AUTOSAR XML (schema 00046)
package /ComponentTypes
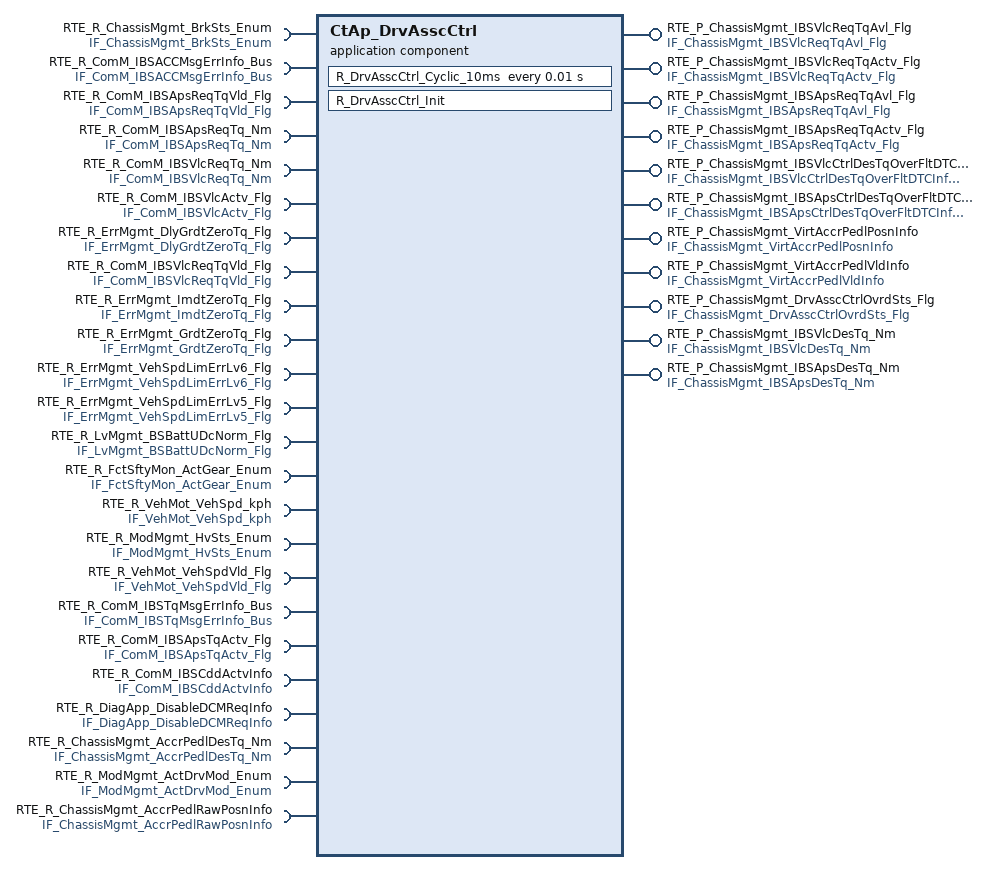
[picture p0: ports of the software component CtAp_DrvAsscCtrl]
  application sw component type CtAp_DrvAsscCtrl
    4 x provide port:
      RTE_P_ChassisMgmt_IBSVlcReqTqAvl_Flg: nonqueued-sender-com-spec{data-element=tec_ChassisMgmt_IBSVlcReqTqAvl_Flg, init-value=0}, provided-interface=IF_ChassisMgmt_IBSVlcReqTqAvl_Flg
      RTE_P_ChassisMgmt_IBSVlcReqTqActv_Flg: nonqueued-sender-com-spec{data-element=tec_ChassisMgmt_IBSVlcReqTqActv_Flg, init-value=0}, provided-interface=IF_ChassisMgmt_IBSVlcReqTqActv_Flg
      RTE_P_ChassisMgmt_IBSApsReqTqAvl_Flg: nonqueued-sender-com-spec{data-element=tec_ChassisMgmt_IBSApsReqTqAvl_Flg, init-value=0}, provided-interface=IF_ChassisMgmt_IBSApsReqTqAvl_Flg
      RTE_P_ChassisMgmt_IBSApsReqTqActv_Flg: nonqueued-sender-com-spec{data-element=tec_ChassisMgmt_IBSApsReqTqActv_Flg, init-value=0}, provided-interface=IF_ChassisMgmt_IBSApsReqTqActv_Flg
    16 x require port:
      RTE_R_ChassisMgmt_BrkSts_Enum: nonqueued-receiver-com-spec{data-element=tec_ChassisMgmt_BrkSts_Enum, filter=data-filter-type=ALWAYS, init-value=0}, required-interface=IF_ChassisMgmt_BrkSts_Enum
      RTE_R_ComM_IBSACCMsgErrInfo_Bus: required-interface=IF_ComM_IBSACCMsgErrInfo_Bus
        required-com-specs:
          data-element=tec_ComM_IBSACCCRCDTCInfo_Bus, filter=data-filter-type=ALWAYS, init-value=fields=[ComM_MonStatIBSACCCRCDTCErrorInfo:0, ComM_MonResIBSACCCRCDTCErrorInfo:0, ComM_ErrStatIBSACCCRCDTCErrorInfo:0, ComM_ErrResIBSACCCRCDTCErrorInfo:0]
          data-element=tec_ComM_IBSACCCRCInfo_Bus, filter=data-filter-type=ALWAYS, init-value=fields=[ComM_MonStatIBSACCCRCErrorInfo:0, ComM_MonResIBSACCCRCErrorInfo:0, ComM_ErrStatIBSACCCRCErrorInfo:0, ComM_ErrResIBSACCCRCErrorInfo:0]
          data-element=tec_ComM_IBSACCTimeoutDTCInfo_Bus, filter=data-filter-type=ALWAYS, init-value=fields=[ComM_MonStatIBSACCTimeoutDTCErrorInfo:0, ComM_MonResIBSACCTimeoutDTCErrorInfo:0, ComM_ErrStatIBSACCTimeoutDTCErrorInfo:0, ComM_ErrResIBSACCTimeoutDTCErrorInfo:0]
          data-element=tec_ComM_IBSACCE2ETimeoutInfo_Bus, filter=data-filter-type=ALWAYS, init-value=fields=[ComM_MonStatIBSACCE2ETimeoutInfo:0, ComM_MonResIBSACCE2ETimeoutInfo:0, ComM_ErrStatIBSACCE2ETimeoutInfo:0, ComM_ErrResIBSACCE2ETimeoutInfo:0]
      RTE_R_ComM_IBSApsReqTqVld_Flg: nonqueued-receiver-com-spec{data-element=tec_ComM_IBSApsReqTqVld_Flg, filter=data-filter-type=ALWAYS, init-value=0}, required-interface=IF_ComM_IBSApsReqTqVld_Flg
      RTE_R_ComM_IBSApsReqTq_Nm: nonqueued-receiver-com-spec{data-element=tec_ComM_IBSApsReqTq_Nm, filter=data-filter-type=ALWAYS, init-value=0}, required-interface=IF_ComM_IBSApsReqTq_Nm
      RTE_R_ComM_IBSVlcReqTq_Nm: nonqueued-receiver-com-spec{data-element=tec_ComM_IBSVlcReqTq_Nm, filter=data-filter-type=ALWAYS, init-value=0}, required-interface=IF_ComM_IBSVlcReqTq_Nm
      RTE_R_ComM_IBSVlcActv_Flg: nonqueued-receiver-com-spec{data-element=tec_ComM_IBSVlcActv_Flg, filter=data-filter-type=ALWAYS, init-value=0}, required-interface=IF_ComM_IBSVlcActv_Flg
      RTE_R_ErrMgmt_DlyGrdtZeroTq_Flg: nonqueued-receiver-com-spec{data-element=tec_ErrMgmt_DlyGrdtZeroTq_Flg, filter=data-filter-type=ALWAYS, init-value=0}, required-interface=IF_ErrMgmt_DlyGrdtZeroTq_Flg
      RTE_R_ComM_IBSVlcReqTqVld_Flg: nonqueued-receiver-com-spec{data-element=tec_ComM_IBSVlcReqTqVld_Flg, filter=data-filter-type=ALWAYS, init-value=0}, required-interface=IF_ComM_IBSVlcReqTqVld_Flg
      RTE_R_ErrMgmt_ImdtZeroTq_Flg: nonqueued-receiver-com-spec{data-element=tec_ErrMgmt_ImdtZeroTq_Flg, filter=data-filter-type=ALWAYS, init-value=0}, required-interface=IF_ErrMgmt_ImdtZeroTq_Flg
      RTE_R_ErrMgmt_GrdtZeroTq_Flg: nonqueued-receiver-com-spec{data-element=tec_ErrMgmt_GrdtZeroTq_Flg, filter=data-filter-type=ALWAYS, init-value=0}, required-interface=IF_ErrMgmt_GrdtZeroTq_Flg
      RTE_R_ErrMgmt_VehSpdLimErrLv6_Flg: nonqueued-receiver-com-spec{data-element=tec_ErrMgmt_VehSpdLimErrLv6_Flg, filter=data-filter-type=ALWAYS, init-value=0}, required-interface=IF_ErrMgmt_VehSpdLimErrLv6_Flg
      RTE_R_ErrMgmt_VehSpdLimErrLv5_Flg: nonqueued-receiver-com-spec{data-element=tec_ErrMgmt_VehSpdLimErrLv5_Flg, filter=data-filter-type=ALWAYS, init-value=0}, required-interface=IF_ErrMgmt_VehSpdLimErrLv5_Flg
      RTE_R_LvMgmt_BSBattUDcNorm_Flg: nonqueued-receiver-com-spec{data-element=tec_LvMgmt_BSBattUDcNorm_Flg, filter=data-filter-type=ALWAYS, init-value=0}, required-interface=IF_LvMgmt_BSBattUDcNorm_Flg
      RTE_R_FctSftyMon_ActGear_Enum: nonqueued-receiver-com-spec{data-element=tec_FctSftyMon_ActGear_Enum, filter=data-filter-type=ALWAYS, init-value=0}, required-interface=IF_FctSftyMon_ActGear_Enum
      RTE_R_VehMot_VehSpd_kph: nonqueued-receiver-com-spec{data-element=tec_VehMot_VehSpd_kph, filter=data-filter-type=ALWAYS, init-value=0}, required-interface=IF_VehMot_VehSpd_kph
      RTE_R_ModMgmt_HvSts_Enum: nonqueued-receiver-com-spec{data-element=tec_ModMgmt_HvSts_Enum, filter=data-filter-type=ALWAYS, init-value=0}, required-interface=IF_ModMgmt_HvSts_Enum
    provide port RTE_P_ChassisMgmt_IBSVlcCtrlDesTqOverFltDTCInfo_Bus: nonqueued-sender-com-spec{data-element=tec_ChassisMgmt_IBSVlcCtrlDesTqOverFltDTCInfo_Bus, init-value=fields=[ChassisMgmt_MonStatIBSVlcCtrlDesTqOverFltDTCInfo:0, ChassisMgmt_MonResIBSVlcCtrlDesTqOverFltDTCInfo:0, ChassisMgmt_ErrStatIBSVlcCtrlDesTqOverFltDTCInfo:0, ChassisMgmt_ErrResIBSVlcCtrlDesTqOverFltDTCInfo:0]}, provided-interface=IF_ChassisMgmt_IBSVlcCtrlDesTqOverFltDTCInfo_Bus
    provide port RTE_P_ChassisMgmt_IBSApsCtrlDesTqOverFltDTCInfo_Bus: nonqueued-sender-com-spec{data-element=tec_ChassisMgmt_IBSApsCtrlDesTqOverFltDTCInfo_Bus, init-value=fields=[ChassisMgmt_MonStatIBSApsCtrlDesTqOverFltDTCInfo:0, ChassisMgmt_MonResIBSApsCtrlDesTqOverFltDTCInfo:0, ChassisMgmt_ErrStatIBSApsCtrlDesTqOverFltDTCInfo:0, ChassisMgmt_ErrResIBSApsCtrlDesTqOverFltDTCInfo:0]}, provided-interface=IF_ChassisMgmt_IBSApsCtrlDesTqOverFltDTCInfo_Bus
    4 x require port:
      RTE_R_VehMot_VehSpdVld_Flg: nonqueued-receiver-com-spec{data-element=tec_VehMot_VehSpdVld_Flg, filter=data-filter-type=ALWAYS, init-value=0}, required-interface=IF_VehMot_VehSpdVld_Flg
      RTE_R_ComM_IBSTqMsgErrInfo_Bus: required-interface=IF_ComM_IBSTqMsgErrInfo_Bus
        required-com-specs:
          data-element=tec_ComM_IBSTqCRCDTCInfo_Bus, filter=data-filter-type=ALWAYS, init-value=fields=[ComM_MonStatIBSTqCRCDTCErrorInfo:0, ComM_MonResIBSTqCRCDTCErrorInfo:0, ComM_ErrStatIBSTqCRCDTCErrorInfo:0, ComM_ErrResIBSTqCRCDTCErrorInfo:0]
          data-element=tec_ComM_IBSTqTimeoutDTCInfo_Bus, filter=data-filter-type=ALWAYS, init-value=fields=[ComM_MonStatIBSTqTimeoutDTCErrorInfo:0, ComM_MonResIBSTqTimeoutDTCErrorInfo:0, ComM_ErrStatIBSTqTimeoutDTCErrorInfo:0, ComM_ErrResIBSTqTimeoutDTCErrorInfo:0]
          data-element=tec_ComM_IBSTqCRCInfo_Bus, filter=data-filter-type=ALWAYS, init-value=fields=[ComM_MonStatIBSTqCRCErrorInfo:0, ComM_MonResIBSTqCRCErrorInfo:0, ComM_ErrStatIBSTqCRCErrorInfo:0, ComM_ErrResIBSTqCRCErrorInfo:0]
          data-element=tec_ComM_IBSTqE2ETimeoutInfo_Bus, filter=data-filter-type=ALWAYS, init-value=fields=[ComM_MonStatIBSTqE2ETimeoutInfo:0, ComM_MonResIBSTqE2ETimeoutInfo:0, ComM_ErrStatIBSTqE2ETimeoutInfo:0, ComM_ErrResIBSTqE2ETimeoutInfo:0]
      RTE_R_ComM_IBSApsTqActv_Flg: nonqueued-receiver-com-spec{data-element=tec_ComM_IBSApsTqActv_Flg, filter=data-filter-type=ALWAYS, init-value=0}, required-interface=IF_ComM_IBSApsTqActv_Flg
      RTE_R_ComM_IBSCddActvInfo: nonqueued-receiver-com-spec{data-element=tec_ComM_IBSCddActvInfo, filter=data-filter-type=ALWAYS, init-value=0}, required-interface=IF_ComM_IBSCddActvInfo
    provide port RTE_P_ChassisMgmt_VirtAccrPedlPosnInfo: nonqueued-sender-com-spec{data-element=tec_ChassisMgmt_VirtAccrPedlPosnInfo, init-value=0}, provided-interface=IF_ChassisMgmt_VirtAccrPedlPosnInfo
    provide port RTE_P_ChassisMgmt_VirtAccrPedlVldInfo: nonqueued-sender-com-spec{data-element=tec_ChassisMgmt_VirtAccrPedlVldInfo, init-value=0}, provided-interface=IF_ChassisMgmt_VirtAccrPedlVldInfo
    require port RTE_R_DiagApp_DisableDCMReqInfo: nonqueued-receiver-com-spec{data-element=tec_DiagApp_DisableDCMReqInfo, filter=data-filter-type=ALWAYS, init-value=0}, required-interface=IF_DiagApp_DisableDCMReqInfo
    require port RTE_R_ChassisMgmt_AccrPedlDesTq_Nm: nonqueued-receiver-com-spec{data-element=tec_ChassisMgmt_AccrPedlDesTq_Nm, filter=data-filter-type=ALWAYS, init-value=0}, required-interface=IF_ChassisMgmt_AccrPedlDesTq_Nm
    require port RTE_R_ModMgmt_ActDrvMod_Enum: nonqueued-receiver-com-spec{data-element=tec_ModMgmt_ActDrvMod_Enum, filter=data-filter-type=ALWAYS, init-value=0}, required-interface=IF_ModMgmt_ActDrvMod_Enum
    provide port RTE_P_ChassisMgmt_DrvAsscCtrlOvrdSts_Flg: nonqueued-sender-com-spec{data-element=tec_ChassisMgmt_DrvAsscCtrlOvrdSts_Flg, init-value=0}, provided-interface=IF_ChassisMgmt_DrvAsscCtrlOvrdSts_Flg
    provide port RTE_P_ChassisMgmt_IBSVlcDesTq_Nm: nonqueued-sender-com-spec{data-element=tec_ChassisMgmt_IBSVlcDesTq_Nm, init-value=0}, provided-interface=IF_ChassisMgmt_IBSVlcDesTq_Nm
    provide port RTE_P_ChassisMgmt_IBSApsDesTq_Nm: nonqueued-sender-com-spec=tec_ChassisMgmt_IBSApsDesTq_Nm, provided-interface=IF_ChassisMgmt_IBSApsDesTq_Nm
    require port RTE_R_ChassisMgmt_AccrPedlRawPosnInfo: nonqueued-receiver-com-spec{data-element=tec_ChassisMgmt_AccrPedlRawPosnInfo, filter=data-filter-type=ALWAYS, init-value=0}, required-interface=IF_ChassisMgmt_AccrPedlRawPosnInfo
    behavior CtAp_DrvAsscCtrl_InternalBehavior
      timing event TMT_R_DrvAsscCtrl_Cyclic_10ms: start-on-event=R_DrvAsscCtrl_Cyclic_10ms, period=0.01
      init event CtAp_DrvAsscCtrl_InitEvent: start-on-event=R_DrvAsscCtrl_Init
      runnable R_DrvAsscCtrl_Cyclic_10ms
        data-receive-point-by-arguments:
          26 x access:
            REC_RTE_R_ChassisMgmt_BrkSts_Enum_tec_ChassisMgmt_BrkSts_Enum: accessed-variable=RTE_R_ChassisMgmt_BrkSts_Enum.tec_ChassisMgmt_BrkSts_Enum
            REC_RTE_R_ComM_IBSACCMsgErrInfo_Bus_tec_ComM_IBSACCCRCInfo_Bus: accessed-variable=RTE_R_ComM_IBSACCMsgErrInfo_Bus.tec_ComM_IBSACCCRCInfo_Bus
            REC_RTE_R_ComM_IBSACCMsgErrInfo_Bus_tec_ComM_IBSACCE2ETimeoutInfo_Bus: accessed-variable=RTE_R_ComM_IBSACCMsgErrInfo_Bus.tec_ComM_IBSACCE2ETimeoutInfo_Bus
            REC_RTE_R_ComM_IBSApsReqTqVld_Enum_tec_ComM_IBSApsReqTqVld_Enum: accessed-variable=RTE_R_ComM_IBSApsReqTqVld_Flg.tec_ComM_IBSApsReqTqVld_Flg
            REC_RTE_R_ComM_IBSApsReqTq_Nm_tec_ComM_IBSApsReqTq_Nm: accessed-variable=RTE_R_ComM_IBSApsReqTq_Nm.tec_ComM_IBSApsReqTq_Nm
            REC_RTE_R_ComM_IBSVlcActv_Flg_tec_ComM_IBSVlcActv_Flg: accessed-variable=RTE_R_ComM_IBSVlcActv_Flg.tec_ComM_IBSVlcActv_Flg
            REC_RTE_R_ComM_IBSVlcReqTqVld_Flg_tec_ComM_IBSVlcReqTqVld_Flg: accessed-variable=RTE_R_ComM_IBSVlcReqTqVld_Flg.tec_ComM_IBSVlcReqTqVld_Flg
            REC_RTE_R_ComM_IBSVlcReqTq_Nm_tec_ComM_IBSVlcReqTq_Nm: accessed-variable=RTE_R_ComM_IBSVlcReqTq_Nm.tec_ComM_IBSVlcReqTq_Nm
            REC_RTE_R_ErrMgmt_DlyGrdtZeroTq_Flg_tec_ErrMgmt_DlyGrdtZeroTq_Flg: accessed-variable=RTE_R_ErrMgmt_DlyGrdtZeroTq_Flg.tec_ErrMgmt_DlyGrdtZeroTq_Flg
            REC_RTE_R_ErrMgmt_GrdtZeroTq_Flg_tec_ErrMgmt_GrdtZeroTq_Flg: accessed-variable=RTE_R_ErrMgmt_GrdtZeroTq_Flg.tec_ErrMgmt_GrdtZeroTq_Flg
            REC_RTE_R_ErrMgmt_ImdtZeroTq_Flg_tec_ErrMgmt_ImdtZeroTq_Flg: accessed-variable=RTE_R_ErrMgmt_ImdtZeroTq_Flg.tec_ErrMgmt_ImdtZeroTq_Flg
            REC_RTE_R_ErrMgmt_VehSpdLimErrLv5_Flg_tec_ErrMgmt_VehSpdLimErrLv5_Flg: accessed-variable=RTE_R_ErrMgmt_VehSpdLimErrLv5_Flg.tec_ErrMgmt_VehSpdLimErrLv5_Flg
            REC_RTE_R_ErrMgmt_VehSpdLimErrLv6_Flg_tec_ErrMgmt_VehSpdLimErrLv6_Flg: accessed-variable=RTE_R_ErrMgmt_VehSpdLimErrLv6_Flg.tec_ErrMgmt_VehSpdLimErrLv6_Flg
            REC_RTE_R_FctSftyMon_ActGear_Enum_tec_FctSftyMon_ActGear_Enum: accessed-variable=RTE_R_FctSftyMon_ActGear_Enum.tec_FctSftyMon_ActGear_Enum
            REC_RTE_R_LvMgmt_BSBattUDcNorm_Flg_tec_LvMgmt_BSBattUDcNorm_Flg: accessed-variable=RTE_R_LvMgmt_BSBattUDcNorm_Flg.tec_LvMgmt_BSBattUDcNorm_Flg
            REC_RTE_R_ModMgmt_HvSts_Enum_tec_ModMgmt_HvSts_Enum: accessed-variable=RTE_R_ModMgmt_HvSts_Enum.tec_ModMgmt_HvSts_Enum
            REC_RTE_R_VehMot_VehSpd_kph_tec_VehMot_VehSpd_kph: accessed-variable=RTE_R_VehMot_VehSpd_kph.tec_VehMot_VehSpd_kph
            REC_RTE_R_ComM_IBSApsTqActv_Flg_tec_ComM_IBSApsTqActv_Flg: accessed-variable=RTE_R_ComM_IBSApsTqActv_Flg.tec_ComM_IBSApsTqActv_Flg
            REC_RTE_R_ComM_IBSTqMsgErrInfo_Bus_tec_ComM_IBSTqCRCInfo_Bus: accessed-variable=RTE_R_ComM_IBSTqMsgErrInfo_Bus.tec_ComM_IBSTqCRCInfo_Bus
            REC_RTE_R_ComM_IBSTqMsgErrInfo_Bus_tec_ComM_IBSTqE2ETimeoutInfo_Bus: accessed-variable=RTE_R_ComM_IBSTqMsgErrInfo_Bus.tec_ComM_IBSTqE2ETimeoutInfo_Bus
            REC_RTE_R_VehMot_VehSpdVld_Flg_tec_VehMot_VehSpdVld_Flg: accessed-variable=RTE_R_VehMot_VehSpdVld_Flg.tec_VehMot_VehSpdVld_Flg
            REC_RTE_R_ComM_IBSCddActvInfo_tec_ComM_IBSCddActvInfo: accessed-variable=RTE_R_ComM_IBSCddActvInfo.tec_ComM_IBSCddActvInfo
            REC_RTE_R_DiagApp_DisableDCMReqInfo_tec_DiagApp_DisableDCMReqInfo: accessed-variable=RTE_R_DiagApp_DisableDCMReqInfo.tec_DiagApp_DisableDCMReqInfo
            REC_RTE_R_ChassisMgmt_AccrPedlDesTq_Nm_tec_ChassisMgmt_AccrPedlDesTq_Nm: accessed-variable=RTE_R_ChassisMgmt_AccrPedlDesTq_Nm.tec_ChassisMgmt_AccrPedlDesTq_Nm
            REC_RTE_R_ModMgmt_ActDrvMod_Enum_tec_ModMgmt_ActDrvMod_Enum: accessed-variable=RTE_R_ModMgmt_ActDrvMod_Enum.tec_ModMgmt_ActDrvMod_Enum
            REC_RTE_R_ChassisMgmt_AccrPedlRawPosnInfo_tec_ChassisMgmt_AccrPedlRawPosnInfo: accessed-variable=RTE_R_ChassisMgmt_AccrPedlRawPosnInfo.tec_ChassisMgmt_AccrPedlRawPosnInfo
        data-send-points:
          11 x access:
            SEND_RTE_P_ChassisMgmt_IBSApsReqTqActv_Flg_tec_ChassisMgmt_IBSApsReqTqActv_Flg: accessed-variable=RTE_P_ChassisMgmt_IBSApsReqTqActv_Flg.tec_ChassisMgmt_IBSApsReqTqActv_Flg
            SEND_RTE_P_ChassisMgmt_IBSApsReqTqAvl_Flg_tec_ChassisMgmt_IBSApsReqTqAvl_Flg: accessed-variable=RTE_P_ChassisMgmt_IBSApsReqTqAvl_Flg.tec_ChassisMgmt_IBSApsReqTqAvl_Flg
            SEND_RTE_P_ChassisMgmt_IBSVlcReqTqActv_Flg_tec_ChassisMgmt_IBSVlcReqTqActv_Flg: accessed-variable=RTE_P_ChassisMgmt_IBSVlcReqTqActv_Flg.tec_ChassisMgmt_IBSVlcReqTqActv_Flg
            SEND_RTE_P_ChassisMgmt_IBSVlcReqTqAvl_Flg_tec_ChassisMgmt_IBSVlcReqTqAvl_Flg: accessed-variable=RTE_P_ChassisMgmt_IBSVlcReqTqAvl_Flg.tec_ChassisMgmt_IBSVlcReqTqAvl_Flg
            SEND_RTE_P_ChassisMgmt_IBSApsCtrlDesTqOverFltDTCInfo_Bus_tec_ChassisMgmt_IBSApsCtrlDesTqOverFltDTCInfo_Bus: accessed-variable=RTE_P_ChassisMgmt_IBSApsCtrlDesTqOverFltDTCInfo_Bus.tec_ChassisMgmt_IBSApsCtrlDesTqOverFltDTCInfo_Bus
            SEND_RTE_P_ChassisMgmt_IBSVlcCtrlDesTqOverFltDTCInfo_Bus_tec_ChassisMgmt_IBSVlcCtrlDesTqOverFltDTCInfo_Bus: accessed-variable=RTE_P_ChassisMgmt_IBSVlcCtrlDesTqOverFltDTCInfo_Bus.tec_ChassisMgmt_IBSVlcCtrlDesTqOverFltDTCInfo_Bus
            SEND_RTE_P_ChassisMgmt_VirtAccrPedlPosnInfo_tec_ChassisMgmt_VirtAccrPedlPosnInfo: accessed-variable=RTE_P_ChassisMgmt_VirtAccrPedlPosnInfo.tec_ChassisMgmt_VirtAccrPedlPosnInfo
            SEND_RTE_P_ChassisMgmt_VirtAccrPedlVldInfo_tec_ChassisMgmt_VirtAccrPedlVldInfo: accessed-variable=RTE_P_ChassisMgmt_VirtAccrPedlVldInfo.tec_ChassisMgmt_VirtAccrPedlVldInfo
            SEND_RTE_P_ChassisMgmt_DrvAsscCtrlOvrdSts_Flg_tec_ChassisMgmt_DrvAsscCtrlOvrdSts_Flg: accessed-variable=RTE_P_ChassisMgmt_DrvAsscCtrlOvrdSts_Flg.tec_ChassisMgmt_DrvAsscCtrlOvrdSts_Flg
            SEND_RTE_P_ChassisMgmt_IBSApsDesTq_Nm_tec_ChassisMgmt_IBSApsDesTq_Nm: accessed-variable=RTE_P_ChassisMgmt_IBSApsDesTq_Nm.tec_ChassisMgmt_IBSApsDesTq_Nm
            SEND_RTE_P_ChassisMgmt_IBSVlcDesTq_Nm_tec_ChassisMgmt_IBSVlcDesTq_Nm: accessed-variable=RTE_P_ChassisMgmt_IBSVlcDesTq_Nm.tec_ChassisMgmt_IBSVlcDesTq_Nm
      runnable R_DrvAsscCtrl_Init
  swc implementation CtAp_DrvAsscCtrl_Implementation: behavior=CtAp_DrvAsscCtrl_InternalBehavior
